# entropy_source: IP-XACT component
VLNV tenstorrent.com:ocah:entropy_source:1.0

## Address spaces and blocks
entropy_source_mmap.entropy_source: base 'h0, range 'h17c, width 32

## Registers
Registers are 32-bit, read-write, reset 0x0 unless marked. A register's access mark holds for its fields unless they carry their own. Offsets are from the block's base; lines under a group give offsets from that group; [hi:lo] are bit positions; {n}, {i} and the like mark numbered series; 'fields as' and 'values as' point back to an identical list; <NAME> marks a mode.

## entropy_source_mmap.entropy_source — Entropy-source configuration, status, and data registers.
Base 0x00000000
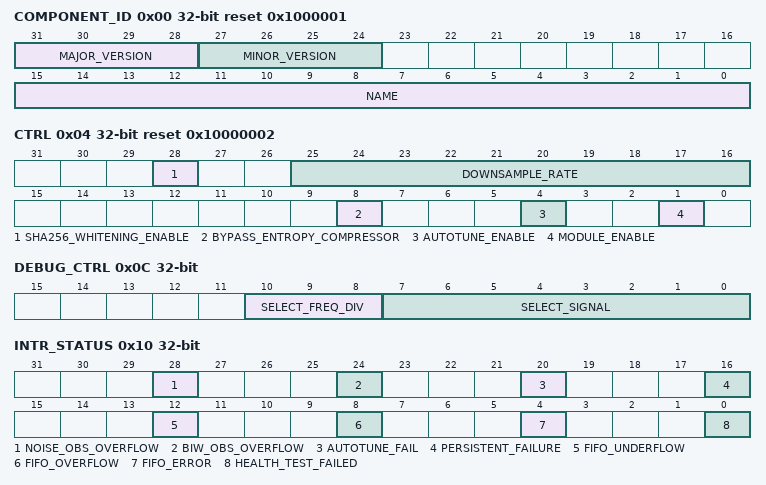
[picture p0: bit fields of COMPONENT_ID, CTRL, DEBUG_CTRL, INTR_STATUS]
0x00 COMPONENT_ID ro reset 0x1000001 — Identifies the entropy-source register interface.
  [31:28] MAJOR_VERSION — Major interface version.
  [27:24] MINOR_VERSION — Minor interface version.
  [15:0] NAME — Entropy-source component identifier.
0x04 CTRL access per field reset 0x10000002 — Controls entropy generation and conditioning.
  [28] SHA256_WHITENING_ENABLE rw — Enables SHA-256 conditioning of each 512-bit BIW input block into a 256-bit digest. When clear, BIW words pass directly to the FIFO. FIPS_LOCK.LOCK prevents software changes.
  [25:16] DOWNSAMPLE_RATE rw — Selects every (N+1)th decorrelator output while BIW extraction is bypassed. FIPS_LOCK.LOCK prevents software changes.
  [8] BYPASS_ENTROPY_COMPRESSOR rw — Bypasses BIW extraction and writes the twelve generator bytes to the FIFO as three 32-bit words, word 0 first, with generator 4n+k in bits [8k+7:8k] of word n. FIPS_LOCK.LOCK prevents software changes.
  [4] AUTOTUNE_ENABLE rw — Enables per-generator automatic detuning after a lane health-test failure. FIPS_LOCK.LOCK prevents software changes.
  [1] MODULE_ENABLE rw — Enables startup health testing and entropy output. Clearing this field holds the main state machine idle. FIPS_LOCK.LOCK prevents software changes.
0x0C DEBUG_CTRL — Controls the external debug observation pin. FIPS_LOCK.LOCK prevents software changes to the signal selection and divider.
  [10:8] SELECT_FREQ_DIV — Selects observation division by 1, 2, 4, 8, 16, 32, 64, or 128. FIPS_LOCK.LOCK prevents software changes.
  [7:0] SELECT_SIGNAL — Selects the observed signal: generator noise bits [11:0], sample clocks [27:16], BIW data [63:32], FIFO input [95:64], or generator bytes [223:128]. Other selections drive the divider input low. FIPS_LOCK.LOCK prevents software changes.
0x10 INTR_STATUS — Reports latched interrupt status; write one to clear a bit.
  [28] NOISE_OBS_OVERFLOW write-1-clears — Indicates that a raw-noise observe FIFO word was discarded while full. Write one to clear.
  [24] BIW_OBS_OVERFLOW write-1-clears — Indicates that a BIW observe FIFO word was discarded while full. Write one to clear.
  [20] AUTOTUNE_FAIL write-1-clears — Indicates a per-generator health-test failure while automatic detuning is enabled. Write one to clear.
  [16] PERSISTENT_FAILURE write-1-clears — Indicates a persistent health-test failure or health-test counter error. Write one to clear.
  [12] FIFO_UNDERFLOW write-1-clears — Indicates that software read the empty main FIFO. Write one to clear.
  [8] FIFO_OVERFLOW write-1-clears — Indicates that a main FIFO write was discarded while full. Write one to clear.
  [4] FIFO_ERROR write-1-clears — Indicates a FIFO integrity error. Write one to clear.
  [0] HEALTH_TEST_FAILED write-1-clears — Indicates a failure in the 32-bit entropy-stream health tests. Write one to clear.
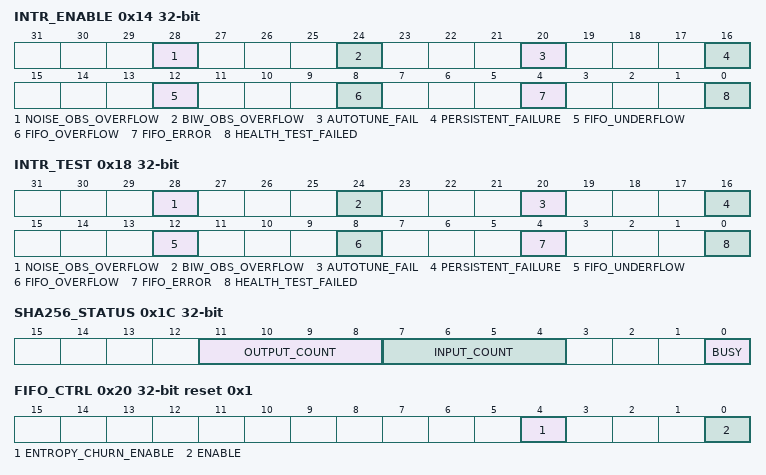
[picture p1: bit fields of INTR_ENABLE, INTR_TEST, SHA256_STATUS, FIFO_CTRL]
0x14 INTR_ENABLE — Enables individual interrupt sources.
  [28] NOISE_OBS_OVERFLOW — Enables the raw-noise observe FIFO overflow interrupt.
  [24] BIW_OBS_OVERFLOW — Enables the BIW observe FIFO overflow interrupt.
  [20] AUTOTUNE_FAIL — Enables the automatic-detuning failure interrupt.
  [16] PERSISTENT_FAILURE — Enables the persistent-failure interrupt.
  [12] FIFO_UNDERFLOW — Enables the main FIFO underflow interrupt.
  [8] FIFO_OVERFLOW — Enables the main FIFO overflow interrupt.
  [4] FIFO_ERROR — Enables the FIFO integrity-error interrupt.
  [0] HEALTH_TEST_FAILED — Enables the health-test failure interrupt.
0x18 INTR_TEST wo — Triggers individual interrupt sources for testing.
  [28] NOISE_OBS_OVERFLOW — Write one to pulse the raw-noise observe FIFO overflow interrupt source.
  [24] BIW_OBS_OVERFLOW — Write one to pulse the BIW observe FIFO overflow interrupt source.
  [20] AUTOTUNE_FAIL — Write one to pulse the automatic-detuning failure interrupt source.
  [16] PERSISTENT_FAILURE — Write one to pulse the persistent-failure interrupt source.
  [12] FIFO_UNDERFLOW — Write one to pulse the main FIFO underflow interrupt source.
  [8] FIFO_OVERFLOW — Write one to pulse the main FIFO overflow interrupt source.
  [4] FIFO_ERROR — Write one to pulse the FIFO integrity-error interrupt source.
  [0] HEALTH_TEST_FAILED — Write one to pulse the health-test failure interrupt source.
0x1C SHA256_STATUS ro — Reports SHA-256 conditioner progress.
  [11:8] OUTPUT_COUNT — Number of 32-bit digest words remaining for output. Reports 8 when a digest becomes available, decrements through 0 as words are accepted, and remains 0 while idle or bypassed.
  [7:4] INPUT_COUNT — Number of 32-bit words currently accumulated in the 512-bit input block.
  [0] BUSY — Indicates that SHA-256 processing or digest output is active.
0x20 FIFO_CTRL reset 0x1 — Controls the 64-entry main entropy FIFO.
  [4] ENTROPY_CHURN_ENABLE — XORs each incoming word with the FIFO entry 32 positions ahead of the write pointer. FIPS_LOCK.LOCK prevents software changes.
  [0] ENABLE — Enables FIFO writes. Reads remain available while writes are disabled. Words offered to the FIFO are also the DRBG seed stream, which this field does not gate. FIPS_LOCK.LOCK prevents software changes.
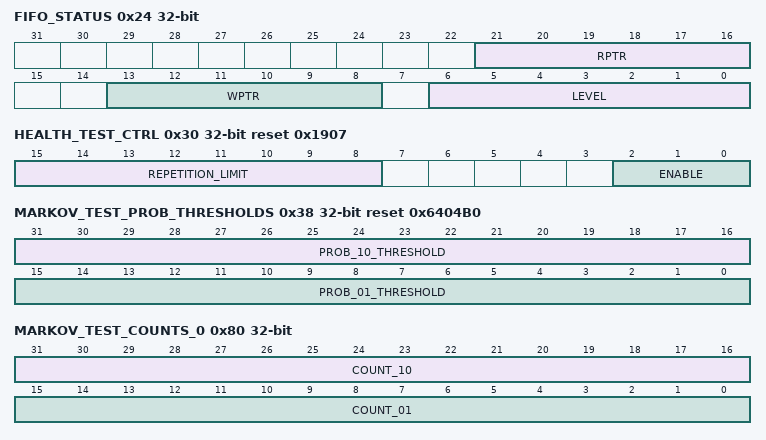
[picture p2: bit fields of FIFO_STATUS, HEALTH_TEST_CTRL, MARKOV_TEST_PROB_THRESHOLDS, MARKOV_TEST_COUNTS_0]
0x24 FIFO_STATUS ro — Reports main FIFO occupancy and pointers.
  [21:16] RPTR — Current FIFO read pointer.
  [13:8] WPTR — Current FIFO write pointer.
  [6:0] LEVEL — Number of valid 32-bit words in the FIFO.
0x28 FIFO_RDATA ro — Provides the next main FIFO word.
  [31:0] RDATA read-modifies — Returns and removes the next FIFO word. Reading an empty FIFO sets INTR_STATUS.FIFO_UNDERFLOW and returns undefined data.
0x30 HEALTH_TEST_CTRL reset 0x1907 — Controls continuous entropy health tests.
  [15:8] REPETITION_LIMIT — Maximum allowed per-lane repetition count before the test fails. FIPS_LOCK.LOCK prevents software changes.
  [2:0] ENABLE — Enables the repetition-count, adaptive-proportion, and Markov tests in bits 0, 1, and 2. Disabling a test clears its state.
0x34 HEALTH_TEST_WINDOW_SIZE reset 0x800 — Sets the APT and Markov window length.
  [15:0] SIZE — Number of valid entropy words per APT and Markov window. FIPS_LOCK.LOCK requires a value of at least 1024 and prevents software changes.
0x38 MARKOV_TEST_PROB_THRESHOLDS reset 0x6404B0 — Sets high and low Markov alternation-count thresholds.
  [31:16] PROB_10_THRESHOLD — Minimum allowed per-lane alternation count at the window boundary. FIPS_LOCK.LOCK prevents software changes.
  [15:0] PROB_01_THRESHOLD — Maximum allowed per-lane alternation count at the window boundary. FIPS_LOCK.LOCK prevents software changes.
0x40 HEALTH_TEST_STATUS — Latches 32-bit stream health-test failures: repetition [0], APT high or low [3], Markov high [4], and Markov low [5]. Write one to clear.
  [7:0] HEALTH_STATUS write-1-clears — Latched health-test failure bits; write one to clear.
0x44 REPETITION_TEST_COUNT ro — Reports the highest current repetition count.
  [15:0] REPETITION_COUNT — Highest current repetition count among the 32 entropy lanes.
0x50 APT_PATTERN_COUNT_1BIT ro — Reports the highest per-lane APT one-count in the current window.
  [15:0] PATTERN_COUNT — Highest current one-count among the 32 entropy lanes.
0x54 APT_PATTERN_COUNT_2BIT ro — Reports the lowest per-lane APT one-count in the current window.
  [15:0] PATTERN_COUNT — Lowest current one-count among the 32 entropy lanes.
0x60 APT_PROPORTION_1BIT reset 0x4B0 — Sets the APT high one-count threshold.
  [15:0] LIMIT — Maximum allowed per-lane one-count at the window boundary. FIPS_LOCK.LOCK prevents software changes.
0x70 APT_PROPORTION_LO reset 0x350 — Sets the APT low one-count threshold.
  [15:0] LIMIT — Minimum allowed per-lane one-count at the window boundary. Zero disables the low-side test. FIPS_LOCK.LOCK prevents software changes.
0x80 MARKOV_TEST_COUNTS_0 ro — Reports the highest and lowest per-lane alternation counts in the current Markov window.
  [31:16] COUNT_10 — Lowest current per-lane alternation count.
  [15:0] COUNT_01 — Highest current per-lane alternation count.
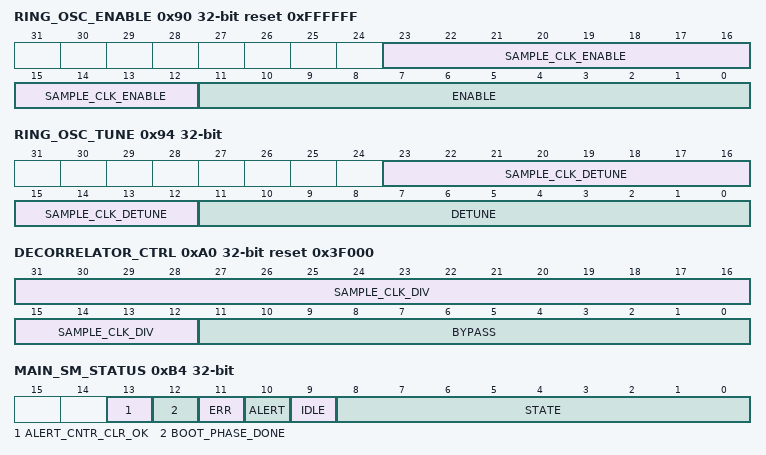
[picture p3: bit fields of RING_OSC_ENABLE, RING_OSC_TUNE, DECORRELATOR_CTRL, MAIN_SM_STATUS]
0x90 RING_OSC_ENABLE reset 0xFFFFFF — Controls noise and sample-clock ring oscillators.
  [23:12] SAMPLE_CLK_ENABLE — Enables the shared sample-clock ring oscillator when any bit is set. FIPS_LOCK.LOCK prevents software changes.
  [11:0] ENABLE — Enables each generator noise ring oscillator. FIPS_LOCK.LOCK prevents software changes.
0x94 RING_OSC_TUNE — Selects detuned ring-oscillator tap points.
  [23:12] SAMPLE_CLK_DETUNE — Selects the full-length (longer) shared sample-clock oscillator tap, lowering its frequency, when any bit is set. FIPS_LOCK.LOCK prevents software changes.
  [11:0] DETUNE — Selects the full-length (longer) tap for each noise ring oscillator, lowering its frequency, while automatic tuning is disabled; the reset value (clear) selects the shorter tap. FIPS_LOCK.LOCK prevents software changes.
0x98 RING_OSC_CTRL reset 0xFFF — Selects each generator sample-clock source.
  [11:0] SAMPLE_CLK_SELECT — Selects the shared internal sample clock when set and the external sample clock when clear. FIPS_LOCK.LOCK prevents software changes.
0xA0 DECORRELATOR_CTRL reset 0x3F000 — Controls generator decorrelation and byte cadence.
  [31:12] SAMPLE_CLK_DIV — Sets the generator byte-output period to this value plus one sample-clock cycles. FIPS_LOCK.LOCK prevents software changes.
  [11:0] BYPASS — Bypasses the LFSR feedback path independently for each generator. FIPS_LOCK.LOCK prevents software changes.
0xA4 DECORRELATOR_MASK reset 0xFF — Masks bits in every generator entropy byte.
  [7:0] ENTROPY_BYTE_MASK — Enables corresponding entropy-byte bits when set. FIPS_LOCK.LOCK prevents software changes.
0xB4 MAIN_SM_STATUS access per field — Reports the startup health-test gate state machine.
  [13] ALERT_CNTR_CLR_OK ro — Indicates that a passing window may clear alert failure counters.
  [12] BOOT_PHASE_DONE ro — Indicates successful completion of startup health testing and permits entropy output.
  [11] ERR rw write-1-clears — Latches an illegal state or health-test counter integrity error. Write one or reset the block to clear.
  [10] ALERT rw write-1-clears — Latches entry into the persistent-failure alert path, which halts entropy output. Write one or reset the block to clear.
  [9] IDLE ro — Indicates that the state machine is idle.
  [8:0] STATE ro — Current sparse-encoded state-machine state.
{0xC0+4i} GENERATOR_{i}_HEALTH_STATUS (i=0..11) — Latches generator {i} health-test failures; write one to clear.
  [7:0] STATUS write-1-clears — Generator {i} failure bits use the HEALTH_TEST_STATUS allocation.
0x100 GENERATOR_0_SAMPLE_CLK_CONFIG — Controls generator 0 sample-clock division.
  [4:0] SAMPLE_CLK_DIVIDE — Selects division by 1, 2, 4, 8, 16, or 32. FIPS_LOCK.LOCK prevents software changes.
0x104 GENERATOR_1_SAMPLE_CLK_CONFIG — Controls generator 1 sample-clock division.
  fields as GENERATOR_0_SAMPLE_CLK_CONFIG
0x108 GENERATOR_2_SAMPLE_CLK_CONFIG reset 0x1 — Controls generator 2 sample-clock division.
  fields as GENERATOR_0_SAMPLE_CLK_CONFIG
0x10C GENERATOR_3_SAMPLE_CLK_CONFIG reset 0x1 — Controls generator 3 sample-clock division.
  fields as GENERATOR_0_SAMPLE_CLK_CONFIG
0x110 GENERATOR_4_SAMPLE_CLK_CONFIG reset 0x2 — Controls generator 4 sample-clock division.
  fields as GENERATOR_0_SAMPLE_CLK_CONFIG
0x114 GENERATOR_5_SAMPLE_CLK_CONFIG reset 0x2 — Controls generator 5 sample-clock division.
  fields as GENERATOR_0_SAMPLE_CLK_CONFIG
0x118 GENERATOR_6_SAMPLE_CLK_CONFIG — Controls generator 6 sample-clock division.
  fields as GENERATOR_0_SAMPLE_CLK_CONFIG
0x11C GENERATOR_7_SAMPLE_CLK_CONFIG — Controls generator 7 sample-clock division.
  fields as GENERATOR_0_SAMPLE_CLK_CONFIG
0x120 GENERATOR_8_SAMPLE_CLK_CONFIG reset 0x1 — Controls generator 8 sample-clock division.
  fields as GENERATOR_0_SAMPLE_CLK_CONFIG
0x124 GENERATOR_9_SAMPLE_CLK_CONFIG reset 0x1 — Controls generator 9 sample-clock division.
  fields as GENERATOR_0_SAMPLE_CLK_CONFIG
0x128 GENERATOR_10_SAMPLE_CLK_CONFIG reset 0x2 — Controls generator 10 sample-clock division.
  fields as GENERATOR_0_SAMPLE_CLK_CONFIG
0x12C GENERATOR_11_SAMPLE_CLK_CONFIG reset 0x2 — Controls generator 11 sample-clock division.
  fields as GENERATOR_0_SAMPLE_CLK_CONFIG
0x130 HT_WATERMARK_NUM — Selects the counter and direction for the shared health-test watermark. Changing the selection preserves the current watermark.
  [3:0] WATERMARK_NUM — Selects the watermark source. Unsupported values select REPCNT_HI.
    0=REPCNT_HI (Tracks the highest repetition count.); 1=APT_HI (Tracks the highest APT count.); 2=APT_LO (Tracks the lowest APT count.); 3=MARKOV_HI (Tracks the highest Markov count.); 4=MARKOV_LO (Tracks the lowest Markov count.)
0x134 HT_WATERMARK ro — Reports one selector-dependent watermark. A CTRL.MODULE_ENABLE rising edge arms high modes to zero and low modes to 0xFFFF.
  [15:0] WATERMARK_VALUE — Current shared watermark value.
0x138 REPCNT_TOTAL_FAILS ro — Counts repetition-test failures since the last CTRL.MODULE_ENABLE rising edge.
  [31:0] FAIL_COUNT — Total repetition-test failure pulses.
0x13C APT_HI_TOTAL_FAILS ro — Counts APT high-threshold failures since the last CTRL.MODULE_ENABLE rising edge.
  [31:0] FAIL_COUNT — Total APT high-threshold failure pulses.
0x140 APT_LO_TOTAL_FAILS ro — Counts APT low-threshold failures since the last CTRL.MODULE_ENABLE rising edge.
  [31:0] FAIL_COUNT — Total APT low-threshold failure pulses.
0x144 MARKOV_HI_TOTAL_FAILS ro — Counts Markov high-threshold failures since the last CTRL.MODULE_ENABLE rising edge.
  [31:0] FAIL_COUNT — Total Markov high-threshold failure pulses.
0x148 MARKOV_LO_TOTAL_FAILS ro — Counts Markov low-threshold failures since the last CTRL.MODULE_ENABLE rising edge.
  [31:0] FAIL_COUNT — Total Markov low-threshold failure pulses.
0x14C ALERT_SUMMARY_FAIL_COUNTS ro — Counts consecutive health-test windows containing any failure and clears after an accepted passing window.
  [15:0] ANY_FAIL_COUNT — Number of consecutive failing health-test windows.
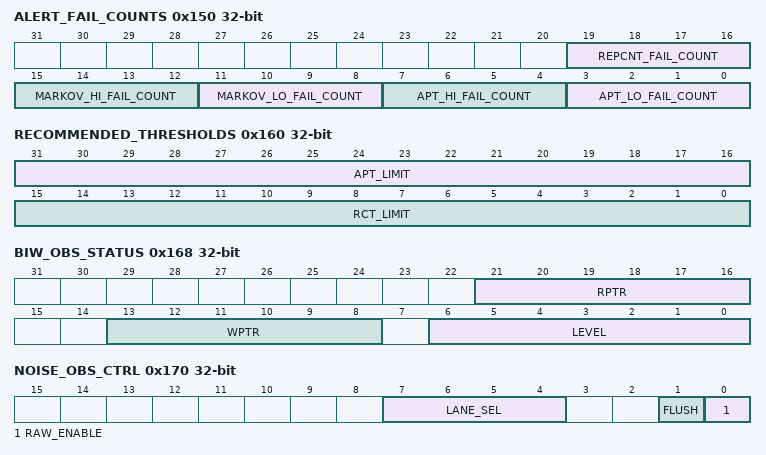
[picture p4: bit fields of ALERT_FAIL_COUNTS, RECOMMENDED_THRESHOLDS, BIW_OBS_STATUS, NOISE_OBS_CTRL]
0x150 ALERT_FAIL_COUNTS ro — Reports saturating per-test failure counts for the current alert sequence.
  [19:16] REPCNT_FAIL_COUNT — Saturating repetition-test failure count.
  [15:12] MARKOV_HI_FAIL_COUNT — Saturating Markov high-threshold failure count.
  [11:8] MARKOV_LO_FAIL_COUNT — Saturating Markov low-threshold failure count.
  [7:4] APT_HI_FAIL_COUNT — Saturating APT high-threshold failure count.
  [3:0] APT_LO_FAIL_COUNT — Saturating APT low-threshold failure count.
0x154 FIPS_LOCK — Locks entropy generation, conditioning, and health-test configuration against software writes until hardware reset.
  [0] LOCK write-1-sets — Write one to set the configuration lock. Only hardware reset clears it.
0x158 ALERT_THRESHOLD reset 0x4 — Sets the failing-window count that enters the persistent-failure alert path.
  [15:0] THRESHOLD — Number of consecutive failing windows that triggers the alert; zero disables this trigger. FIPS_LOCK.LOCK prevents software changes.
0x15C MIN_ENTROPY_H reset 0xC — Stores assessed per-sample min-entropy in unsigned Q4.4 format for advisory threshold calculation.
  [7:0] H — Assessed min-entropy in bits per sample. FIPS_LOCK.LOCK prevents software changes.
0x160 RECOMMENDED_THRESHOLDS ro — Reports advisory repetition and APT thresholds derived from MIN_ENTROPY_H.
  [31:16] APT_LIMIT — Advisory APT high cutoff derived for a 1024-sample window.
  [15:0] RCT_LIMIT — Advisory repetition-count cutoff C = 1 + ceil(20 / H).
0x164 BIW_OBS_CTRL — Controls copy-only capture of the post-BIW, pre-SHA stream.
  [0] RAW_ENABLE — Enables capture after startup health testing completes. FIPS_LOCK.LOCK prevents software changes.
0x168 BIW_OBS_STATUS ro — Reports BIW observe FIFO occupancy and pointers.
  [21:16] RPTR — Current BIW observe FIFO read pointer.
  [13:8] WPTR — Current BIW observe FIFO write pointer.
  [6:0] LEVEL — Number of valid 32-bit words in the BIW observe FIFO.
0x16C BIW_OBS_RDATA ro — Provides the next post-BIW, pre-SHA observe word.
  [31:0] RDATA read-modifies — Returns and removes the next BIW observe FIFO word.
0x170 NOISE_OBS_CTRL access per field — Controls copy-only capture of one pre-decorrelator generator lane.
  [7:4] LANE_SEL rw — Selects generator lane 0 through 11; other values select lane 0. Changing lanes restarts packing and flushes buffered words.
  [1] FLUSH wo — Write one to discard buffered raw-noise words. Changing LANE_SEL also flushes the FIFO.
  [0] RAW_ENABLE rw — Enables LSB-first packing of selected-lane samples into 32-bit observe words. FIPS_LOCK.LOCK prevents software changes.
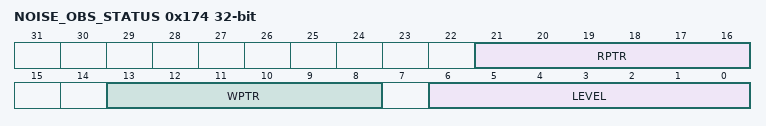
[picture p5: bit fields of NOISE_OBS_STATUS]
0x174 NOISE_OBS_STATUS ro — Reports raw-noise observe FIFO occupancy and pointers.
  [21:16] RPTR — Current raw-noise observe FIFO read pointer.
  [13:8] WPTR — Current raw-noise observe FIFO write pointer.
  [6:0] LEVEL — Number of valid 32-bit words in the raw-noise observe FIFO.
0x178 NOISE_OBS_RDATA ro — Provides the next packed raw-noise observe word.
  [31:0] RDATA read-modifies — Returns and removes 32 LSB-first pre-decorrelator samples from the selected lane.

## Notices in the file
SPDX-License-Identifier: Apache-2.0
SPDX-FileCopyrightText: 2026 Tenstorrent USA, Inc.
